# ATSAMV71Q21 register map
Vendor: Microchip Technology; Series: SAMV71; File version: 0
CPU: CM7 r1p1, little endian, MPU, FPU, 3 interrupt priority bits
Registers are 32-bit, access not given, no defined reset value unless marked. A register's access mark holds for its fields unless they carry their own. Offsets are from the block's base; [hi:lo] are bit positions; lines under a group give offsets from that group; {n}, {i} and the like mark numbered series.

## RSTC — Reset Controller
Base 0x400E1800; register names take the prefix RSTC_
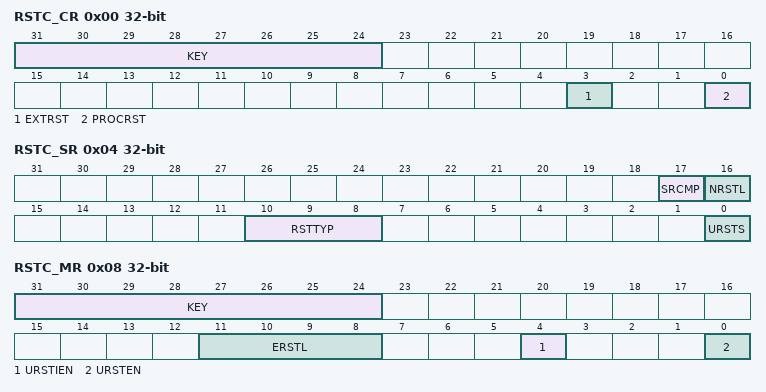
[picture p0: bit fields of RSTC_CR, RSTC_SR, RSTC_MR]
0x00 RSTC_CR wo — Control Register
  [31:24] KEY — System Reset Key
    165=PASSWD (Writing any other value in this field aborts the write operation.)
  [3] EXTRST — External Reset
  [0] PROCRST — Processor Reset
0x04 RSTC_SR ro — Status Register
  [17] SRCMP — Software Reset Command in Progress
  [16] NRSTL — NRST Pin Level
  [10:8] RSTTYP — Reset Type
    0=GENERAL_RST (First powerup reset); 1=BACKUP_RST (Return from Backup mode); 2=WDT_RST (Watchdog fault occurred); 3=SOFT_RST (Processor reset required by the software); 4=USER_RST (NRST pin detected low)
  [0] URSTS — User Reset Status
0x08 RSTC_MR — Mode Register
  [31:24] KEY — Write Access Password
    165=PASSWD (Writing any other value in this field aborts the write operation.Always reads as 0.)
  [11:8] ERSTL — External Reset Length
  [4] URSTIEN — User Reset Interrupt Enable
  [0] URSTEN — User Reset Enable

## RSWDT — Reinforced Safety Watchdog Timer
Base 0x400E1900; register names take the prefix RSWDT_
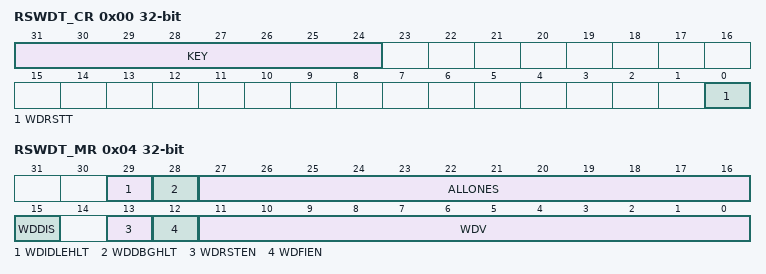
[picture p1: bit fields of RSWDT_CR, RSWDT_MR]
0x00 RSWDT_CR wo — Control Register
  [31:24] KEY — Password
    196=PASSWD (Writing any other value in this field aborts the write operation.)
  [0] WDRSTT — Watchdog Restart
0x04 RSWDT_MR — Mode Register
  [29] WDIDLEHLT — Watchdog Idle Halt
  [28] WDDBGHLT — Watchdog Debug Halt
  [27:16] ALLONES — Must Always Be Written with 0xFFF
  [15] WDDIS — Watchdog Disable
  [13] WDRSTEN — Watchdog Reset Enable
  [12] WDFIEN — Watchdog Fault Interrupt Enable
  [11:0] WDV — Watchdog Counter Value
0x08 RSWDT_SR ro — Status Register
  [0] WDUNF — Watchdog Underflow

## RTT — Real-time Timer
Base 0x400E1830; register names take the prefix RTT_
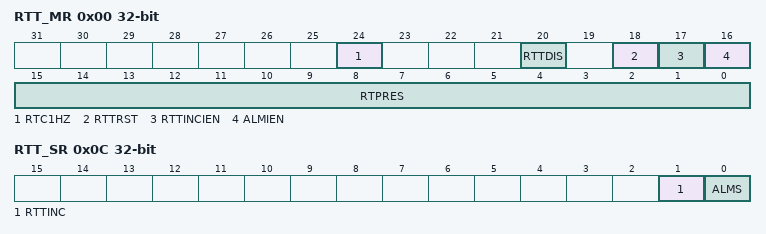
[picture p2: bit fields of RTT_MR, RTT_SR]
0x00 RTT_MR — Mode Register
  [24] RTC1HZ — Real-Time Clock 1Hz Clock Selection
  [20] RTTDIS — Real-time Timer Disable
  [18] RTTRST — Real-time Timer Restart
  [17] RTTINCIEN — Real-time Timer Increment Interrupt Enable
  [16] ALMIEN — Alarm Interrupt Enable
  [15:0] RTPRES — Real-time Timer Prescaler Value
0x04 RTT_AR — Alarm Register
  [31:0] ALMV — Alarm Value
0x08 RTT_VR ro — Value Register
  [31:0] CRTV — Current Real-time Value
0x0C RTT_SR ro — Status Register
  [1] RTTINC — Prescaler Roll-over Status (cleared on read)
  [0] ALMS — Real-time Alarm Status (cleared on read)

## SMC — Static Memory Controller
Base 0x40080000; register names take the prefix SMC_
{0x0+0x10*i} SMC_CS_NUMBER[{i}] (i=0..3) group — SMC Setup Register (CS_number = 0)
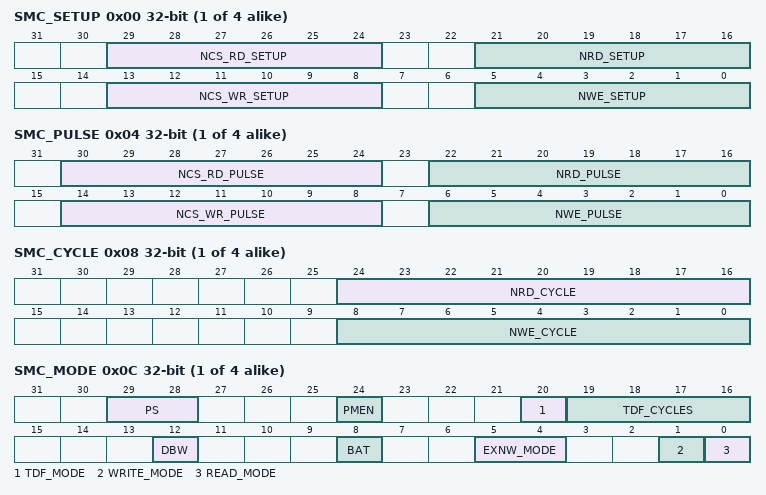
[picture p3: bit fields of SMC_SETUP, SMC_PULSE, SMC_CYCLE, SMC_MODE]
  0x00 SMC_SETUP — SMC Setup Register (CS_number = 0)
    [29:24] NCS_RD_SETUP — NCS Setup Length in READ Access
    [21:16] NRD_SETUP — NRD Setup Length
    [13:8] NCS_WR_SETUP — NCS Setup Length in WRITE Access
    [5:0] NWE_SETUP — NWE Setup Length
  0x04 SMC_PULSE — SMC Pulse Register (CS_number = 0)
    [30:24] NCS_RD_PULSE — NCS Pulse Length in READ Access
    [22:16] NRD_PULSE — NRD Pulse Length
    [14:8] NCS_WR_PULSE — NCS Pulse Length in WRITE Access
    [6:0] NWE_PULSE — NWE Pulse Length
  0x08 SMC_CYCLE — SMC Cycle Register (CS_number = 0)
    [24:16] NRD_CYCLE — Total Read Cycle Length
    [8:0] NWE_CYCLE — Total Write Cycle Length
  0x0C SMC_MODE — SMC Mode Register (CS_number = 0)
    [29:28] PS — Page Size
      0=_4_BYTE (4-byte page); 1=_8_BYTE (8-byte page); 2=_16_BYTE (16-byte page); 3=_32_BYTE (32-byte page)
    [24] PMEN — Page Mode Enabled
    [20] TDF_MODE — TDF Optimization
    [19:16] TDF_CYCLES — Data Float Time
    [12] DBW — Data Bus Width
      0=_8_BIT (8-bit Data Bus); 1=_16_BIT (16-bit Data Bus)
    [8] BAT — Byte Access Type
      0=BYTE_SELECT (Byte select access type:- Write operation is controlled using NCS, NWE, NBS0, NBS1.- Read operation is controlled using NCS, NRD, NBS0, NBS1.); 1=BYTE_WRITE (Byte write access type:- Write operation is controlled using NCS, NWR0, NWR1.- Read operation is controlled using NCS and NRD.)
    [5:4] EXNW_MODE — NWAIT Mode
      0=DISABLED (Disabled-The NWAIT input signal is ignored on the corresponding chip select.); 2=FROZEN (Frozen Mode-If asserted, the NWAIT signal freezes the current read or write cycle. After deassertion, the read/write cycle is resumed from the point where it was stopped.); 3=READY (Ready Mode-The NWAIT signal indicates the availability of the external device at the end of the pulse of the controlling read or write signal, to complete the access. If high, the access normally completes. If low, the access is extended until NWAIT returns high.)
    [1] WRITE_MODE
    [0] READ_MODE
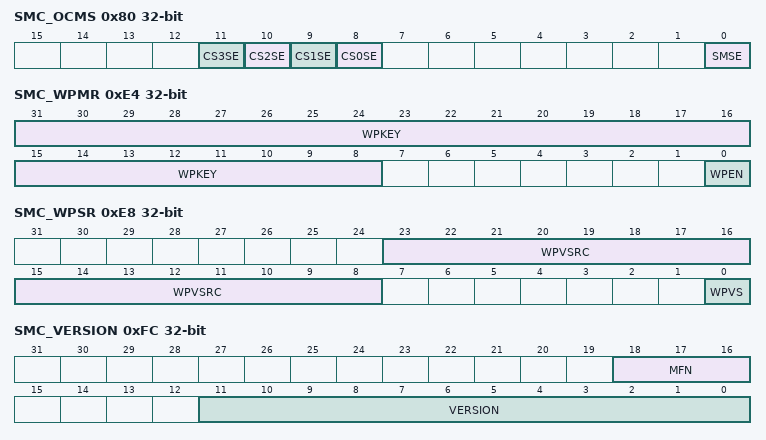
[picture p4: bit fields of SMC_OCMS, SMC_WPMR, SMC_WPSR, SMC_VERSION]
0x80 SMC_OCMS — SMC Off-Chip Memory Scrambling Register
  [n+8] CS{n}SE (n=0..3) — Chip Select (x = 0 to 3) Scrambling Enable
  [0] SMSE — Static Memory Controller Scrambling Enable
0x84 SMC_KEY1 wo — SMC Off-Chip Memory Scrambling KEY1 Register
  [31:0] KEY1 — Off-Chip Memory Scrambling (OCMS) Key Part 1
0x88 SMC_KEY2 wo — SMC Off-Chip Memory Scrambling KEY2 Register
  [31:0] KEY2 — Off-Chip Memory Scrambling (OCMS) Key Part 2
0xE4 SMC_WPMR — SMC Write Protection Mode Register
  [31:8] WPKEY — Write Protection Key
    0x534D43=PASSWD (Writing any other value in this field aborts the write operation of the WPEN bit. Always reads as 0.)
  [0] WPEN — Write Protect Enable
0xE8 SMC_WPSR ro — SMC Write Protection Status Register
  [23:8] WPVSRC — Write Protection Violation Source
  [0] WPVS — Write Protection Violation Status
0xFC SMC_VERSION ro
  [18:16] MFN — Metal Fix Number
  [11:0] VERSION — Hardware Module Version
